AUTOSAR XML (schema 4-0-3)
package /ComponentTypes
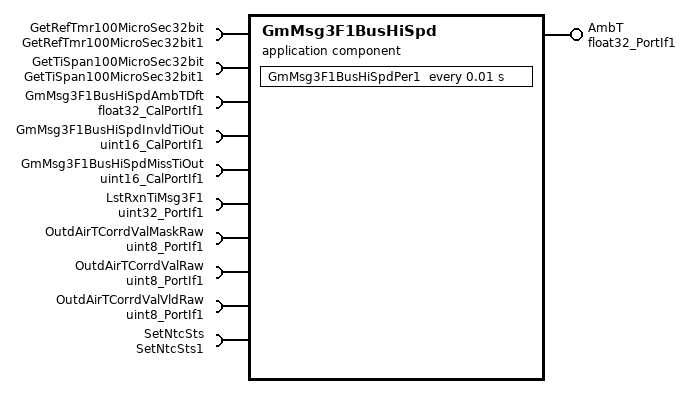
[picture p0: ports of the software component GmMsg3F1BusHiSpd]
  application sw component type GmMsg3F1BusHiSpd
    provide port AmbT: nonqueued-sender-com-spec{data-element=Val, init-value=0}, provided-interface=float32_PortIf1
    10 x require port:
      GetRefTmr100MicroSec32bit: required-interface=GetRefTmr100MicroSec32bit1
      GetTiSpan100MicroSec32bit: required-interface=GetTiSpan100MicroSec32bit1
      GmMsg3F1BusHiSpdAmbTDft: parameter-require-com-spec{init-value=25, parameter=Val}, required-interface=float32_CalPortIf1
      GmMsg3F1BusHiSpdInvldTiOut: parameter-require-com-spec{init-value=5000, parameter=Val}, required-interface=uint16_CalPortIf1
      GmMsg3F1BusHiSpdMissTiOut: parameter-require-com-spec{init-value=500, parameter=Val}, required-interface=uint16_CalPortIf1
      LstRxnTiMsg3F1: nonqueued-receiver-com-spec{data-element=Val, filter=data-filter-type=ALWAYS, init-value=0}, required-interface=uint32_PortIf1
      OutdAirTCorrdValMaskRaw: nonqueued-receiver-com-spec{data-element=Val, filter=data-filter-type=ALWAYS, init-value=0}, required-interface=uint8_PortIf1
      OutdAirTCorrdValRaw: nonqueued-receiver-com-spec{data-element=Val, filter=data-filter-type=ALWAYS, init-value=0}, required-interface=uint8_PortIf1
      OutdAirTCorrdValVldRaw: nonqueued-receiver-com-spec{data-element=Val, filter=data-filter-type=ALWAYS, init-value=0}, required-interface=uint8_PortIf1
      SetNtcSts: required-interface=SetNtcSts1
    behavior GmMsg3F1BusHiSpd_InternalBehavior: data-type-mapping=Nexteer
      ar-typed-per-instance-memorys:
        data GmMsg3F1BusHiSpdInvldMsgTmr: sw-calibration-access=READ-ONLY, type=uint32
      timing event TMT_GM0C9HSPer1: start-on-event=GmMsg3F1BusHiSpdPer1, period=0.01
      runnable GmMsg3F1BusHiSpdPer1
        data-receive-point-by-arguments:
          4 x access:
            REC_Msg3F1HSLstRxnTi_Val: accessed-variable=LstRxnTiMsg3F1.Val
            REC_OutdAirTCorrdVal_Val: accessed-variable=OutdAirTCorrdValRaw.Val
            REC_OutdAirTCorrdValMask_Val: accessed-variable=OutdAirTCorrdValMaskRaw.Val
            REC_OutdAirTCorrdValVld_Val: accessed-variable=OutdAirTCorrdValVldRaw.Val
        data-send-points:
          access SEND_GM3F1HSAmbT_Val: accessed-variable=AmbT.Val
        sync call SC_GetRefTmr100MicroSec32bit_Oper: operation=GetRefTmr100MicroSec32bit.Oper, timeout=0
        sync call SC_GetTiSpan100MicroSec32bit_Oper: operation=GetTiSpan100MicroSec32bit.Oper, timeout=0
        sync call SC_SetNtcSts_Oper: operation=SetNtcSts.Oper, timeout=0
  swc implementation GmMsg3F1BusHiSpd_Implementation: behavior=GmMsg3F1BusHiSpd_InternalBehavior
    code-descriptors:
      code Default: artifact-descriptors=autosar-engineering-object={short-label=Default, category=SWSRC}
